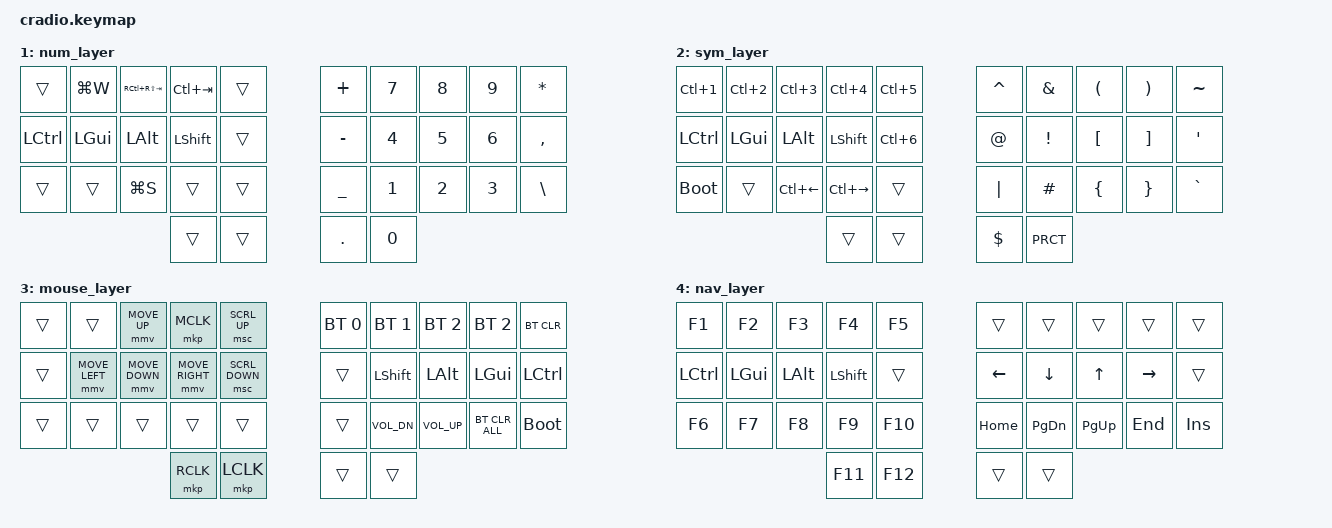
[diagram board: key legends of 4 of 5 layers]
// Copyright (c) 2022 The ZMK Contributors
// SPDX-License-Identifier: MIT

#include <behaviors.dtsi>
#include <dt-bindings/zmk/keys.h>
#include <dt-bindings/zmk/bt.h>

// Mouse settings
#define ZMK_POINTING_DEFAULT_MOVE_VAL 1500  // default: 600
#define ZMK_POINTING_DEFAULT_SCRL_VAL 20    // default: 10

// Mouse functionality
#include <dt-bindings/zmk/pointing.h>

// Home row mods macro
#define HRML(k1,k2,k3,k4) &ht LCTRL k1  &ht LGUI k2  &ht LALT k3  &ht LSHFT k4
#define HRMR(k1,k2,k3,k4) &ht RSHFT k1  &ht LALT k2  &ht LGUI k3  &ht LCTRL k4

// Layers
#define L_DEFAULT 0
#define L_NUM     1
#define L_SYM     2
#define L_MOUSE   3
#define L_NAV     4


/ {
    behaviors {
        ht: hold_tap {
            compatible = "zmk,behavior-hold-tap";
            #binding-cells = <2>;
            flavor = "tap-preferred";
            tapping-term-ms = <180>;
            bindings = <&kp>, <&kp>;
        };
    };

    combos {
        compatible = "zmk,combos";
        combo_capsword { 
            timeout-ms = <50>;
            key-positions = <21 22>;
            layers = <L_DEFAULT>;
            bindings = <&caps_word>;
        };
        combo_tab {
            timeout-ms = <50>;
            key-positions = <22 23>;
            layers = <L_DEFAULT>;
            bindings = <&kp TAB>;
        };
        combo_del {
            timeout-ms = <50>;
            key-positions = <23 24>;
            layers = <L_DEFAULT>;
            bindings = <&kp DEL>;
        };
        combo_eq {
            timeout-ms = <50>;
            key-positions = <26 27>;
            layers = <L_DEFAULT>;
            bindings = <&kp EQUAL>;
        };
        combo_dquote {
            timeout-ms = <50>;
            key-positions = <27 28>;
            layers = <L_DEFAULT>;
            bindings = <&kp DOUBLE_QUOTES>;
        };
    };

    keymap {
        compatible = "zmk,keymap";
        default_layer {
            bindings = <
        //│ 1      │ 2    │ 3    │ 4    │ 5   │ --- │ 6    │ 7      │ 8        │ 9      │ 10       │
           &kp Q    &kp W  &kp E  &kp R  &kp T       &kp Y  &kp U    &kp I      &kp O    &kp P
           HRML(A,  S,     D,     F)     &kp G       &kp H  HRMR(J,  K,         L,       SEMICOLON)
           &kp Z    &kp X  &kp C  &kp V  &kp B       &kp N  &kp M    &kp COMMA  &kp DOT  &kp FSLH
        //     │ thumb 1      │ thumb 2       │ --- │ thumb 3         │ thumb 4        │
                &lt L_NUM ESC  &lt L_SYM SPACE       &lt L_MOUSE BSPC  &lt L_NAV RET
            >;
        };

        num_layer {
            bindings = <
        //│ 1        │ 2        │ 3              │ 4          │ 5    │ --- │ 6             │ 7        │ 8        │ 9        │ 10          │
           &trans     &kp LG(W)  &kp RC(RS(TAB))  &kp LC(TAB)  &trans       &kp PLUS        &kp NUM_7  &kp NUM_8  &kp NUM_9  &kp ASTRK
           &kp LCTRL  &kp LGUI   &kp LALT         &kp LSHFT    &trans       &kp MINUS       &kp NUM_4  &kp NUM_5  &kp NUM_6  &kp COMMA
           &trans     &trans     &kp LG(S)        &trans       &trans       &kp UNDERSCORE  &kp NUM_1  &kp NUM_2  &kp NUM_3  &kp BACKSLASH
                                                  &trans       &trans       &kp DOT         &kp NUM_0
            >;
        };

        sym_layer {
            bindings = <
        //│ 1             │ 2            │ 3            │ 4            │ 5          │ --- │ 6        │ 7       │ 8       │ 9       │ 10      │
           &kp LC(NUM_1)   &kp LC(NUM_2)  &kp LC(NUM_3)  &kp LC(NUM_4)  &kp LC(NUM_5)       &kp CARET  &kp AMPS  &kp LPAR  &kp RPAR  &kp TILDE
           &kp LCTRL       &kp LGUI       &kp LALT       &kp LSHFT      &kp LC(NUM_6)       &kp AT     &kp EXCL  &kp LBKT  &kp RBKT  &kp SQT
           &bootloader     &trans         &kp LC(LEFT)   &kp LC(RIGHT)  &trans              &kp PIPE   &kp HASH  &kp LBRC  &kp RBRC  &kp GRAVE
                                                        &trans         &trans              &kp DLLR   &kp PRCT
            >;
        };

        mouse_layer {
            bindings = <
        //│ 1     │ 2             │ 3             │ 4              │ 5            │ --- │ 6           │ 7           │ 8           │ 9             │ 10       │
           &trans  &trans          &mmv MOVE_UP    &mkp MCLK        &msc SCRL_UP         &bt BT_SEL 0  &bt BT_SEL 1  &bt BT_SEL 2  &bt BT_SEL 2    &bt BT_CLR      
           &trans  &mmv MOVE_LEFT  &mmv MOVE_DOWN  &mmv MOVE_RIGHT  &msc SCRL_DOWN       &trans        &kp LSHFT     &kp LALT      &kp LGUI        &kp LCTRL
           &trans  &trans          &trans          &trans           &trans               &trans        &kp C_VOL_DN  &kp C_VOL_UP  &bt BT_CLR_ALL  &bootloader
                                                   &mkp RCLK        &mkp LCLK            &trans        &trans
            >;
        };

        nav_layer {
            bindings = <
        //│ 1        │ 2       │ 3       │ 4        │ 5     │ --- │ 6       │ 7        │ 8        │ 9        │ 10       │
           &kp F1     &kp F2    &kp F3    &kp F4     &kp F5        &trans    &trans     &trans     &trans     &trans
           &kp LCTRL  &kp LGUI  &kp LALT  &kp LSHFT  &trans        &kp LEFT  &kp DOWN   &kp UP     &kp RIGHT  &trans
           &kp F6     &kp F7    &kp F8    &kp F9     &kp F10       &kp HOME  &kp PG_DN  &kp PG_UP  &kp END    &kp INS
                                          &kp F11    &kp F12       &trans    &trans
            >;
        };
    };
};
